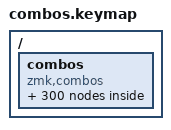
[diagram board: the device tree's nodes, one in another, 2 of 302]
/ {
    combos {
        compatible = "zmk,combos";
        #binding-cells = <2>;

        combo_the {
            key-positions = <12 11 17>;
            bindings      = < &kp T &kp H &kp E >;
        };

        combo_be {
            key-positions = <0 17>;
            bindings      = < &kp B &kp E >;
        };

        combo_and {
            key-positions = <16 9 22>;
            bindings      = < &kp A &kp N &kp D >;
        };

        combo_in {
            key-positions = <18 9>;
            bindings      = < &kp I &kp N >;
        };

        combo_have {
            key-positions = <11 16 20 17>;
            bindings      = < &kp H &kp A &kp V &kp E >;
        };

        combo_it {
            key-positions = <18 12>;
            bindings      = < &kp I &kp T >;
        };

        combo_that {
            key-positions = <12 11 16>;
            bindings      = < &kp T &kp H &kp A >;
        };

        combo_for {
            key-positions = <1 7 25>;
            bindings      = < &kp F &kp O &kp R >;
        };

        combo_you {
            key-positions = <14 7 8>;
            bindings      = < &kp Y &kp O &kp U >;
        };

        combo_he {
            key-positions = <11 17>;
            bindings      = < &kp H &kp E >;
        };

        combo_with {
            key-positions = <24 18 12 11>;
            bindings      = < &kp W &kp I &kp T &kp H >;
        };

        combo_do {
            key-positions = <22 7>;
            bindings      = < &kp D &kp O >;
        };

        combo_say {
            key-positions = <10 16 14>;
            bindings      = < &kp S &kp A &kp Y >;
        };

        combo_this {
            key-positions = <12 11 18 10>;
            bindings      = < &kp T &kp H &kp I &kp S >;
        };

        combo_they {
            key-positions = <12 11 17 14>;
            bindings      = < &kp T &kp H &kp E &kp Y >;
        };

        combo_at {
            key-positions = <16 12>;
            bindings      = < &kp A &kp T >;
        };

        combo_but {
            key-positions = <0 8 12>;
            bindings      = < &kp B &kp U &kp T >;
        };

        combo_we {
            key-positions = <24 17>;
            bindings      = < &kp W &kp E >;
        };

        combo_his {
            key-positions = <11 18 10>;
            bindings      = < &kp H &kp I &kp S >;
        };

        combo_from {
            key-positions = <1 25 7 13>;
            bindings      = < &kp F &kp R &kp O &kp M >;
        };

        combo_not {
            key-positions = <9 7 12>;
            bindings      = < &kp N &kp O &kp T >;
        };

        combo_by {
            key-positions = <0 14>;
            bindings      = < &kp B &kp Y >;
        };

        combo_she {
            key-positions = <10 11 17>;
            bindings      = < &kp S &kp H &kp E >;
        };

        combo_or {
            key-positions = <7 25>;
            bindings      = < &kp O &kp R >;
        };

        combo_as {
            key-positions = <16 10>;
            bindings      = < &kp A &kp S >;
        };

        combo_what {
            key-positions = <24 11 16 12>;
            bindings      = < &kp W &kp H &kp A &kp T >;
        };

        combo_go {
            key-positions = <6 7>;
            bindings      = < &kp G &kp O >;
        };

        combo_their {
            key-positions = <12 11 18>;
            bindings      = < &kp T &kp H &kp I >;
        };

        combo_can {
            key-positions = <15 16 9>;
            bindings      = < &kp C &kp A &kp N >;
        };

        combo_get {
            key-positions = <6 17 12>;
            bindings      = < &kp G &kp E &kp T >;
        };

        combo_if {
            key-positions = <18 1>;
            bindings      = < &kp I &kp F >;
        };

        combo_would {
            key-positions = <24 7 8>;
            bindings      = < &kp W &kp O &kp U >;
        };

        combo_her {
            key-positions = <11 17 25>;
            bindings      = < &kp H &kp E &kp R >;
        };

        combo_all {
            key-positions = <16 2>;
            bindings      = < &kp A &kp L >;
        };

        combo_my {
            key-positions = <13 14>;
            bindings      = < &kp M &kp Y >;
        };

        combo_make {
            key-positions = <13 16 3 17>;
            bindings      = < &kp M &kp A &kp K &kp E >;
        };

        combo_about {
            key-positions = <16 0 7>;
            bindings      = < &kp A &kp B &kp O >;
        };

        combo_know {
            key-positions = <3 9 7 24>;
            bindings      = < &kp K &kp N &kp O &kp W >;
        };

        combo_will {
            key-positions = <24 18 2>;
            bindings      = < &kp W &kp I &kp L >;
        };

        combo_up {
            key-positions = <8 5>;
            bindings      = < &kp U &kp P >;
        };

        combo_one {
            key-positions = <7 9 17>;
            bindings      = < &kp O &kp N &kp E >;
        };

        combo_time {
            key-positions = <12 18 13 17>;
            bindings      = < &kp T &kp I &kp M &kp E >;
        };

        combo_there {
            key-positions = <12 11 17 25>;
            bindings      = < &kp T &kp H &kp E &kp R >;
        };

        combo_year {
            key-positions = <14 17 16 25>;
            bindings      = < &kp Y &kp E &kp A &kp R >;
        };

        combo_so {
            key-positions = <10 7>;
            bindings      = < &kp S &kp O >;
        };

        combo_think {
            key-positions = <12 11 3>;
            bindings      = < &kp T &kp H &kp K >;
        };

        combo_when {
            key-positions = <24 11 17 9>;
            bindings      = < &kp W &kp H &kp E &kp N >;
        };

        combo_which {
            key-positions = <24 11 18 15>;
            bindings      = < &kp W &kp H &kp I &kp C >;
        };

        combo_them {
            key-positions = <12 11 17 13>;
            bindings      = < &kp T &kp H &kp E &kp M >;
        };

        combo_some {
            key-positions = <10 7 13 17>;
            bindings      = < &kp S &kp O &kp M &kp E >;
        };

        combo_me {
            key-positions = <13 17>;
            bindings      = < &kp M &kp E >;
        };

        combo_people {
            key-positions = <5 17 7 2>;
            bindings      = < &kp P &kp E &kp O &kp L >;
        };

        combo_take {
            key-positions = <12 16 3 17>;
            bindings      = < &kp T &kp A &kp K &kp E >;
        };

        combo_out {
            key-positions = <7 8 12>;
            bindings      = < &kp O &kp U &kp T >;
        };

        combo_just {
            key-positions = <21 8 10 12>;
            bindings      = < &kp J &kp U &kp S &kp T >;
        };

        combo_see {
            key-positions = <10 17>;
            bindings      = < &kp S &kp E >;
        };

        combo_him {
            key-positions = <11 18 13>;
            bindings      = < &kp H &kp I &kp M >;
        };

        combo_your {
            key-positions = <14 7 8 25>;
            bindings      = < &kp Y &kp O &kp U &kp R >;
        };

        combo_come {
            key-positions = <15 7 13 17>;
            bindings      = < &kp C &kp O &kp M &kp E >;
        };

        combo_could {
            key-positions = <15 7 8>;
            bindings      = < &kp C &kp O &kp U >;
        };

        combo_now {
            key-positions = <9 7 24>;
            bindings      = < &kp N &kp O &kp W >;
        };

        combo_than {
            key-positions = <12 11 16 9>;
            bindings      = < &kp T &kp H &kp A &kp N >;
        };

        combo_like {
            key-positions = <2 18 3 17>;
            bindings      = < &kp L &kp I &kp K &kp E >;
        };

        combo_how {
            key-positions = <11 7 24>;
            bindings      = < &kp H &kp O &kp W >;
        };

        combo_then {
            key-positions = <12 11 17 9>;
            bindings      = < &kp T &kp H &kp E &kp N >;
        };

        combo_two {
            key-positions = <12 24 7>;
            bindings      = < &kp T &kp W &kp O >;
        };

        combo_more {
            key-positions = <13 7 25 17>;
            bindings      = < &kp M &kp O &kp R &kp E >;
        };

        combo_these {
            key-positions = <12 11 17 10>;
            bindings      = < &kp T &kp H &kp E &kp S >;
        };

        combo_want {
            key-positions = <24 16 9 12>;
            bindings      = < &kp W &kp A &kp N &kp T >;
        };

        combo_way {
            key-positions = <24 16 14>;
            bindings      = < &kp W &kp A &kp Y >;
        };

        combo_look {
            key-positions = <2 7 3>;
            bindings      = < &kp L &kp O &kp K >;
        };

        combo_first {
            key-positions = <1 18 25>;
            bindings      = < &kp F &kp I &kp R >;
        };

        combo_also {
            key-positions = <16 2 10 7>;
            bindings      = < &kp A &kp L &kp S &kp O >;
        };

        combo_new {
            key-positions = <9 17 24>;
            bindings      = < &kp N &kp E &kp W >;
        };

        combo_day {
            key-positions = <22 16 14>;
            bindings      = < &kp D &kp A &kp Y >;
        };

        combo_use {
            key-positions = <8 10 17>;
            bindings      = < &kp U &kp S &kp E >;
        };

        combo_man {
            key-positions = <13 16 9>;
            bindings      = < &kp M &kp A &kp N >;
        };

        combo_find {
            key-positions = <1 18 9 22>;
            bindings      = < &kp F &kp I &kp N &kp D >;
        };

        combo_thing {
            key-positions = <12 11 9>;
            bindings      = < &kp T &kp H &kp N >;
        };

        combo_give {
            key-positions = <6 18 20 17>;
            bindings      = < &kp G &kp I &kp V &kp E >;
        };

        combo_many {
            key-positions = <13 16 9 14>;
            bindings      = < &kp M &kp A &kp N &kp Y >;
        };

        combo_well {
            key-positions = <24 17 2>;
            bindings      = < &kp W &kp E &kp L >;
        };

        combo_only {
            key-positions = <7 9 2 14>;
            bindings      = < &kp O &kp N &kp L &kp Y >;
        };

        combo_those {
            key-positions = <12 11 10>;
            bindings      = < &kp T &kp H &kp S >;
        };

        combo_tell {
            key-positions = <12 17 2>;
            bindings      = < &kp T &kp E &kp L >;
        };

        combo_even {
            key-positions = <17 20 9>;
            bindings      = < &kp E &kp V &kp N >;
        };

        combo_back {
            key-positions = <0 16 15 3>;
            bindings      = < &kp B &kp A &kp C &kp K >;
        };

        combo_any {
            key-positions = <16 9 14>;
            bindings      = < &kp A &kp N &kp Y >;
        };

        combo_good {
            key-positions = <6 7 22>;
            bindings      = < &kp G &kp O &kp D >;
        };

        combo_woman {
            key-positions = <24 7 13>;
            bindings      = < &kp W &kp O &kp M >;
        };

        combo_through {
            key-positions = <12 11 25>;
            bindings      = < &kp T &kp H &kp R >;
        };

        combo_us {
            key-positions = <8 10>;
            bindings      = < &kp U &kp S >;
        };

        combo_life {
            key-positions = <2 18 1 17>;
            bindings      = < &kp L &kp I &kp F &kp E >;
        };

        combo_child {
            key-positions = <15 11 2>;
            bindings      = < &kp C &kp H &kp L >;
        };

        combo_work {
            key-positions = <24 7 25 3>;
            bindings      = < &kp W &kp O &kp R &kp K >;
        };

        combo_down {
            key-positions = <22 7 24 9>;
            bindings      = < &kp D &kp O &kp W &kp N >;
        };

        combo_may {
            key-positions = <13 16 14>;
            bindings      = < &kp M &kp A &kp Y >;
        };

        combo_after {
            key-positions = <16 1 17>;
            bindings      = < &kp A &kp F &kp E >;
        };

        combo_should {
            key-positions = <10 11 7>;
            bindings      = < &kp S &kp H &kp O >;
        };

        combo_call {
            key-positions = <15 16 2>;
            bindings      = < &kp C &kp A &kp L >;
        };

        combo_world {
            key-positions = <24 7 25>;
            bindings      = < &kp W &kp O &kp R >;
        };

        combo_over {
            key-positions = <7 20 17 25>;
            bindings      = < &kp O &kp V &kp E &kp R >;
        };

        combo_school {
            key-positions = <10 15 11>;
            bindings      = < &kp S &kp C &kp H >;
        };

        combo_still {
            key-positions = <10 12 18 2>;
            bindings      = < &kp S &kp T &kp I &kp L >;
        };

        combo_try {
            key-positions = <12 25 14>;
            bindings      = < &kp T &kp R &kp Y >;
        };

        combo_last {
            key-positions = <2 16 10 12>;
            bindings      = < &kp L &kp A &kp S &kp T >;
        };

        combo_ask {
            key-positions = <16 10 3>;
            bindings      = < &kp A &kp S &kp K >;
        };

        combo_too {
            key-positions = <12 7>;
            bindings      = < &kp T &kp O >;
        };

        combo_feel {
            key-positions = <1 17 2>;
            bindings      = < &kp F &kp E &kp L >;
        };

        combo_state {
            key-positions = <10 12 16 17>;
            bindings      = < &kp S &kp T &kp A &kp E >;
        };

        combo_never {
            key-positions = <9 17 20 25>;
            bindings      = < &kp N &kp E &kp V &kp R >;
        };

        combo_between {
            key-positions = <0 17 12>;
            bindings      = < &kp B &kp E &kp T >;
        };

        combo_high {
            key-positions = <11 18 6>;
            bindings      = < &kp H &kp I &kp G >;
        };

        combo_most {
            key-positions = <13 7 10 12>;
            bindings      = < &kp M &kp O &kp S &kp T >;
        };

        combo_much {
            key-positions = <13 8 15 11>;
            bindings      = < &kp M &kp U &kp C &kp H >;
        };

        combo_family {
            key-positions = <1 16 13>;
            bindings      = < &kp F &kp A &kp M >;
        };

        combo_leave {
            key-positions = <2 17 16 20>;
            bindings      = < &kp L &kp E &kp A &kp V >;
        };

        combo_put {
            key-positions = <5 8 12>;
            bindings      = < &kp P &kp U &kp T >;
        };

        combo_old {
            key-positions = <7 2 22>;
            bindings      = < &kp O &kp L &kp D >;
        };

        combo_while {
            key-positions = <24 11 18>;
            bindings      = < &kp W &kp H &kp I >;
        };

        combo_keep {
            key-positions = <3 17 5>;
            bindings      = < &kp K &kp E &kp P >;
        };

        combo_student {
            key-positions = <10 22 9>;
            bindings      = < &kp S &kp D &kp N >;
        };

        combo_why {
            key-positions = <24 11 14>;
            bindings      = < &kp W &kp H &kp Y >;
        };

        combo_great {
            key-positions = <6 25 17>;
            bindings      = < &kp G &kp R &kp E >;
        };

        combo_same {
            key-positions = <10 16 13 17>;
            bindings      = < &kp S &kp A &kp M &kp E >;
        };

        combo_big {
            key-positions = <0 18 6>;
            bindings      = < &kp B &kp I &kp G >;
        };

        combo_group {
            key-positions = <6 25 7>;
            bindings      = < &kp G &kp R &kp O >;
        };

        combo_begin {
            key-positions = <0 17 6>;
            bindings      = < &kp B &kp E &kp G >;
        };

        combo_seem {
            key-positions = <10 17 13>;
            bindings      = < &kp S &kp E &kp M >;
        };

        combo_country {
            key-positions = <15 7 9>;
            bindings      = < &kp C &kp O &kp N >;
        };

        combo_help {
            key-positions = <11 17 2 5>;
            bindings      = < &kp H &kp E &kp L &kp P >;
        };

        combo_talk {
            key-positions = <12 16 2 3>;
            bindings      = < &kp T &kp A &kp L &kp K >;
        };

        combo_where {
            key-positions = <24 11 17 25>;
            bindings      = < &kp W &kp H &kp E &kp R >;
        };

        combo_turn {
            key-positions = <12 8 25 9>;
            bindings      = < &kp T &kp U &kp R &kp N >;
        };

        combo_problem {
            key-positions = <5 25 0>;
            bindings      = < &kp P &kp R &kp B >;
        };

        combo_every {
            key-positions = <17 20 25 14>;
            bindings      = < &kp E &kp V &kp R &kp Y >;
        };

        combo_start {
            key-positions = <10 12 16 25>;
            bindings      = < &kp S &kp T &kp A &kp R >;
        };

        combo_hand {
            key-positions = <11 16 9 22>;
            bindings      = < &kp H &kp A &kp N &kp D >;
        };

        combo_might {
            key-positions = <13 18 6>;
            bindings      = < &kp M &kp I &kp G >;
        };

        combo_show {
            key-positions = <10 11 7 24>;
            bindings      = < &kp S &kp H &kp O &kp W >;
        };

        combo_part {
            key-positions = <5 16 25 12>;
            bindings      = < &kp P &kp A &kp R &kp T >;
        };

        combo_against {
            key-positions = <16 6 18>;
            bindings      = < &kp A &kp G &kp I >;
        };

        combo_place {
            key-positions = <5 2 16>;
            bindings      = < &kp P &kp L &kp A >;
        };

        combo_such {
            key-positions = <10 8 15 11>;
            bindings      = < &kp S &kp U &kp C &kp H >;
        };

        combo_again {
            key-positions = <16 6 18 9>;
            bindings      = < &kp A &kp G &kp I &kp N >;
        };

        combo_few {
            key-positions = <1 17 24>;
            bindings      = < &kp F &kp E &kp W >;
        };

        combo_case {
            key-positions = <15 16 10 17>;
            bindings      = < &kp C &kp A &kp S &kp E >;
        };

        combo_week {
            key-positions = <24 17 3>;
            bindings      = < &kp W &kp E &kp K >;
        };

        combo_company {
            key-positions = <15 13 9>;
            bindings      = < &kp C &kp M &kp N >;
        };

        combo_system {
            key-positions = <10 14 12>;
            bindings      = < &kp S &kp Y &kp T >;
        };

        combo_each {
            key-positions = <17 16 15 11>;
            bindings      = < &kp E &kp A &kp C &kp H >;
        };

        combo_right {
            key-positions = <25 18 6>;
            bindings      = < &kp R &kp I &kp G >;
        };

        combo_hear {
            key-positions = <11 17 16 25>;
            bindings      = < &kp H &kp E &kp A &kp R >;
        };

        combo_question {
            key-positions = <4 8 9>;
            bindings      = < &kp Q &kp U &kp N >;
        };

        combo_during {
            key-positions = <22 8 25>;
            bindings      = < &kp D &kp U &kp R >;
        };

        combo_play {
            key-positions = <5 2 16 14>;
            bindings      = < &kp P &kp L &kp A &kp Y >;
        };

        combo_run {
            key-positions = <25 8 9>;
            bindings      = < &kp R &kp U &kp N >;
        };

        combo_small {
            key-positions = <10 13 16 2>;
            bindings      = < &kp S &kp M &kp A &kp L >;
        };

        combo_number {
            key-positions = <9 8 0>;
            bindings      = < &kp N &kp U &kp B >;
        };

        combo_off {
            key-positions = <7 1>;
            bindings      = < &kp O &kp F >;
        };

        combo_always {
            key-positions = <16 2 24>;
            bindings      = < &kp A &kp L &kp W >;
        };

        combo_move {
            key-positions = <13 7 20 17>;
            bindings      = < &kp M &kp O &kp V &kp E >;
        };

        combo_night {
            key-positions = <9 18 11>;
            bindings      = < &kp N &kp I &kp H >;
        };

        combo_live {
            key-positions = <2 18 20 17>;
            bindings      = < &kp L &kp I &kp V &kp E >;
        };

        combo_point {
            key-positions = <5 7 18>;
            bindings      = < &kp P &kp O &kp I >;
        };

        combo_believe {
            key-positions = <0 17 2>;
            bindings      = < &kp B &kp E &kp L >;
        };

        combo_hold {
            key-positions = <11 7 2 22>;
            bindings      = < &kp H &kp O &kp L &kp D >;
        };

        combo_bring {
            key-positions = <0 25 18>;
            bindings      = < &kp B &kp R &kp I >;
        };

        combo_happen {
            key-positions = <11 16 5>;
            bindings      = < &kp H &kp A &kp P >;
        };

        combo_next {
            key-positions = <9 17 19 12>;
            bindings      = < &kp N &kp E &kp X &kp T >;
        };

        combo_before {
            key-positions = <0 17 1>;
            bindings      = < &kp B &kp E &kp F >;
        };

        combo_large {
            key-positions = <2 16 25>;
            bindings      = < &kp L &kp A &kp R >;
        };

        combo_million {
            key-positions = <13 18 2>;
            bindings      = < &kp M &kp I &kp L >;
        };

        combo_must {
            key-positions = <13 8 10 12>;
            bindings      = < &kp M &kp U &kp S &kp T >;
        };

        combo_home {
            key-positions = <11 7 13 17>;
            bindings      = < &kp H &kp O &kp M &kp E >;
        };

        combo_under {
            key-positions = <8 9 22>;
            bindings      = < &kp U &kp N &kp D >;
        };

        combo_water {
            key-positions = <24 16 17>;
            bindings      = < &kp W &kp A &kp E >;
        };

        combo_room {
            key-positions = <25 7 13>;
            bindings      = < &kp R &kp O &kp M >;
        };

        combo_write {
            key-positions = <24 25 18>;
            bindings      = < &kp W &kp R &kp I >;
        };

        combo_mother {
            key-positions = <13 12 11>;
            bindings      = < &kp M &kp T &kp H >;
        };

        combo_money {
            key-positions = <13 7 9>;
            bindings      = < &kp M &kp O &kp N >;
        };

        combo_story {
            key-positions = <10 12 7>;
            bindings      = < &kp S &kp T &kp O >;
        };

        combo_young {
            key-positions = <14 7 9>;
            bindings      = < &kp Y &kp O &kp N >;
        };

        combo_fact {
            key-positions = <1 16 15 12>;
            bindings      = < &kp F &kp A &kp C &kp T >;
        };

        combo_month {
            key-positions = <13 7 11>;
            bindings      = < &kp M &kp O &kp H >;
        };

        combo_lot {
            key-positions = <2 7 12>;
            bindings      = < &kp L &kp O &kp T >;
        };

        combo_study {
            key-positions = <10 12 8>;
            bindings      = < &kp S &kp T &kp U >;
        };

        combo_book {
            key-positions = <0 7 3>;
            bindings      = < &kp B &kp O &kp K >;
        };

        combo_eye {
            key-positions = <17 14>;
            bindings      = < &kp E &kp Y >;
        };

        combo_word {
            key-positions = <24 7 25 22>;
            bindings      = < &kp W &kp O &kp R &kp D >;
        };

        combo_though {
            key-positions = <12 11 8>;
            bindings      = < &kp T &kp H &kp U >;
        };

        combo_side {
            key-positions = <10 18 22 17>;
            bindings      = < &kp S &kp I &kp D &kp E >;
        };

        combo_four {
            key-positions = <1 7 8 25>;
            bindings      = < &kp F &kp O &kp U &kp R >;
        };

        combo_head {
            key-positions = <11 17 16 22>;
            bindings      = < &kp H &kp E &kp A &kp D >;
        };

        combo_far {
            key-positions = <1 16 25>;
            bindings      = < &kp F &kp A &kp R >;
        };

        combo_black {
            key-positions = <0 2 16>;
            bindings      = < &kp B &kp L &kp A >;
        };

        combo_long {
            key-positions = <2 7 9 6>;
            bindings      = < &kp L &kp O &kp N &kp G >;
        };

        combo_both {
            key-positions = <0 7 12 11>;
            bindings      = < &kp B &kp O &kp T &kp H >;
        };

        combo_little {
            key-positions = <2 18 12 17>;
            bindings      = < &kp L &kp I &kp T &kp E >;
        };

        combo_house {
            key-positions = <11 7 8>;
            bindings      = < &kp H &kp O &kp U >;
        };

        combo_yes {
            key-positions = <14 17 10>;
            bindings      = < &kp Y &kp E &kp S >;
        };

        combo_since {
            key-positions = <10 18 9>;
            bindings      = < &kp S &kp I &kp N >;
        };

        combo_provide {
            key-positions = <5 25 18>;
            bindings      = < &kp P &kp R &kp I >;
        };

        combo_friend {
            key-positions = <1 25 17>;
            bindings      = < &kp F &kp R &kp E >;
        };

        combo_sit {
            key-positions = <10 18 12>;
            bindings      = < &kp S &kp I &kp T >;
        };

        combo_until {
            key-positions = <8 9 12>;
            bindings      = < &kp U &kp N &kp T >;
        };

        combo_power {
            key-positions = <5 7 24>;
            bindings      = < &kp P &kp O &kp W >;
        };

        combo_hour {
            key-positions = <11 7 8 25>;
            bindings      = < &kp H &kp O &kp U &kp R >;
        };

        combo_game {
            key-positions = <6 16 13 17>;
            bindings      = < &kp G &kp A &kp M &kp E >;
        };

        combo_often {
            key-positions = <7 1 12>;
            bindings      = < &kp O &kp F &kp T >;
        };

        combo_yet {
            key-positions = <14 17 12>;
            bindings      = < &kp Y &kp E &kp T >;
        };

        combo_line {
            key-positions = <2 18 9 17>;
            bindings      = < &kp L &kp I &kp N &kp E >;
        };

        combo_end {
            key-positions = <17 9 22>;
            bindings      = < &kp E &kp N &kp D >;
        };

        combo_among {
            key-positions = <16 13 7>;
            bindings      = < &kp A &kp M &kp O >;
        };

        combo_ever {
            key-positions = <17 20 25>;
            bindings      = < &kp E &kp V &kp R >;
        };

        combo_stand {
            key-positions = <10 12 16>;
            bindings      = < &kp S &kp T &kp A >;
        };

        combo_bad {
            key-positions = <0 16 22>;
            bindings      = < &kp B &kp A &kp D >;
        };

        combo_pay {
            key-positions = <5 16 14>;
            bindings      = < &kp P &kp A &kp Y >;
        };

        combo_meet {
            key-positions = <13 17 12>;
            bindings      = < &kp M &kp E &kp T >;
        };

        combo_car {
            key-positions = <15 16 25>;
            bindings      = < &kp C &kp A &kp R >;
        };

        combo_city {
            key-positions = <15 18 12 14>;
            bindings      = < &kp C &kp I &kp T &kp Y >;
        };

        combo_include {
            key-positions = <18 9 15>;
            bindings      = < &kp I &kp N &kp C >;
        };

        combo_continue {
            key-positions = <15 7 18>;
            bindings      = < &kp C &kp O &kp I >;
        };

        combo_name {
            key-positions = <9 16 13 17>;
            bindings      = < &kp N &kp A &kp M &kp E >;
        };

        combo_once {
            key-positions = <7 9 15 17>;
            bindings      = < &kp O &kp N &kp C &kp E >;
        };

        combo_white {
            key-positions = <24 11 12>;
            bindings      = < &kp W &kp H &kp T >;
        };

        combo_least {
            key-positions = <2 16 10>;
            bindings      = < &kp L &kp A &kp S >;
        };

        combo_learn {
            key-positions = <2 17 16>;
            bindings      = < &kp L &kp E &kp A >;
        };

        combo_real {
            key-positions = <25 17 16 2>;
            bindings      = < &kp R &kp E &kp A &kp L >;
        };

        combo_change {
            key-positions = <15 11 16>;
            bindings      = < &kp C &kp H &kp A >;
        };

        combo_team {
            key-positions = <12 17 16 13>;
            bindings      = < &kp T &kp E &kp A &kp M >;
        };

        combo_minute {
            key-positions = <13 18 9>;
            bindings      = < &kp M &kp I &kp N >;
        };

        combo_best {
            key-positions = <0 17 10 12>;
            bindings      = < &kp B &kp E &kp S &kp T >;
        };

        combo_several {
            key-positions = <10 17 20>;
            bindings      = < &kp S &kp E &kp V >;
        };

        combo_idea {
            key-positions = <18 22 17 16>;
            bindings      = < &kp I &kp D &kp E &kp A >;
        };

        combo_body {
            key-positions = <0 7 22 14>;
            bindings      = < &kp B &kp O &kp D &kp Y >;
        };

        combo_nothing {
            key-positions = <9 7 11>;
            bindings      = < &kp N &kp O &kp H >;
        };

        combo_ago {
            key-positions = <16 6 7>;
            bindings      = < &kp A &kp G &kp O >;
        };

        combo_lead {
            key-positions = <2 17 16 22>;
            bindings      = < &kp L &kp E &kp A &kp D >;
        };

        combo_watch {
            key-positions = <24 16 12>;
            bindings      = < &kp W &kp A &kp T >;
        };

        combo_together {
            key-positions = <12 6 11>;
            bindings      = < &kp T &kp G &kp H >;
        };

        combo_follow {
            key-positions = <1 7 2 24>;
            bindings      = < &kp F &kp O &kp L &kp W >;
        };

        combo_parent {
            key-positions = <5 16 17>;
            bindings      = < &kp P &kp A &kp E >;
        };

        combo_stop {
            key-positions = <10 12 7 5>;
            bindings      = < &kp S &kp T &kp O &kp P >;
        };

        combo_face {
            key-positions = <1 16 15 17>;
            bindings      = < &kp F &kp A &kp C &kp E >;
        };

        combo_create {
            key-positions = <15 25 12>;
            bindings      = < &kp C &kp R &kp T >;
        };

        combo_speak {
            key-positions = <10 5 3>;
            bindings      = < &kp S &kp P &kp K >;
        };

        combo_read {
            key-positions = <25 17 16 22>;
            bindings      = < &kp R &kp E &kp A &kp D >;
        };

        combo_level {
            key-positions = <2 17 20>;
            bindings      = < &kp L &kp E &kp V >;
        };

        combo_allow {
            key-positions = <16 2 7 24>;
            bindings      = < &kp A &kp L &kp O &kp W >;
        };

        combo_add {
            key-positions = <16 22>;
            bindings      = < &kp A &kp D >;
        };

        combo_office {
            key-positions = <7 1 18>;
            bindings      = < &kp O &kp F &kp I >;
        };

        combo_spend {
            key-positions = <10 5 9>;
            bindings      = < &kp S &kp P &kp N >;
        };

        combo_door {
            key-positions = <22 7 25>;
            bindings      = < &kp D &kp O &kp R >;
        };

        combo_person {
            key-positions = <5 17 10>;
            bindings      = < &kp P &kp E &kp S >;
        };

        combo_sure {
            key-positions = <10 8 25 17>;
            bindings      = < &kp S &kp U &kp R &kp E >;
        };

        combo_war {
            key-positions = <24 16 25>;
            bindings      = < &kp W &kp A &kp R >;
        };

        combo_history {
            key-positions = <11 18 7>;
            bindings      = < &kp H &kp I &kp O >;
        };

        combo_party {
            key-positions = <5 25 14>;
            bindings      = < &kp P &kp R &kp Y >;
        };

        combo_result {
            key-positions = <25 17 8>;
            bindings      = < &kp R &kp E &kp U >;
        };

        combo_open {
            key-positions = <7 5 17 9>;
            bindings      = < &kp O &kp P &kp E &kp N >;
        };

        combo_morning {
            key-positions = <13 7 18>;
            bindings      = < &kp M &kp O &kp I >;
        };

        combo_walk {
            key-positions = <24 16 2 3>;
            bindings      = < &kp W &kp A &kp L &kp K >;
        };

        combo_reason {
            key-positions = <25 10 9>;
            bindings      = < &kp R &kp S &kp N >;
        };

        combo_low {
            key-positions = <2 7 24>;
            bindings      = < &kp L &kp O &kp W >;
        };

        combo_girl {
            key-positions = <6 18 25 2>;
            bindings      = < &kp G &kp I &kp R &kp L >;
        };

        combo_early {
            key-positions = <17 16 14>;
            bindings      = < &kp E &kp A &kp Y >;
        };

        combo_food {
            key-positions = <1 7 22>;
            bindings      = < &kp F &kp O &kp D >;
        };

        combo_moment {
            key-positions = <13 7 17>;
            bindings      = < &kp M &kp O &kp E >;
        };

        combo_air {
            key-positions = <16 18 25>;
            bindings      = < &kp A &kp I &kp R >;
        };

        combo_force {
            key-positions = <1 7 15>;
            bindings      = < &kp F &kp O &kp C >;
        };

        combo_enough {
            key-positions = <17 9 8>;
            bindings      = < &kp E &kp N &kp U >;
        };

        combo_remember {
            key-positions = <25 17 13 0>;
            bindings      = < &kp R &kp E &kp M &kp B >;
        };

        combo_second {
            key-positions = <10 17 15>;
            bindings      = < &kp S &kp E &kp C >;
        };

        combo_boy {
            key-positions = <0 7 14>;
            bindings      = < &kp B &kp O &kp Y >;
        };

        combo_toward {
            key-positions = <12 7 16>;
            bindings      = < &kp T &kp O &kp A >;
        };

        combo_able {
            key-positions = <16 0 2 17>;
            bindings      = < &kp A &kp B &kp L &kp E >;
        };

        combo_age {
            key-positions = <16 6 17>;
            bindings      = < &kp A &kp G &kp E >;
        };

        combo_love {
            key-positions = <2 7 20 17>;
            bindings      = < &kp L &kp O &kp V &kp E >;
        };

        combo_process {
            key-positions = <5 7 15>;
            bindings      = < &kp P &kp O &kp C >;
        };

        combo_music {
            key-positions = <13 8 10>;
            bindings      = < &kp M &kp U &kp S >;
        };

        combo_consider {
            key-positions = <15 9 22>;
            bindings      = < &kp C &kp N &kp D >;
        };

        combo_appear {
            key-positions = <16 5 17 25>;
            bindings      = < &kp A &kp P &kp E &kp R >;
        };

        combo_buy {
            key-positions = <0 8 14>;
            bindings      = < &kp B &kp U &kp Y >;
        };

        combo_human {
            key-positions = <11 8 13>;
            bindings      = < &kp H &kp U &kp M >;
        };

        combo_wait {
            key-positions = <24 16 18 12>;
            bindings      = < &kp W &kp A &kp I &kp T >;
        };

        combo_serve {
            key-positions = <10 17 25 20>;
            bindings      = < &kp S &kp E &kp R &kp V >;
        };

        combo_market {
            key-positions = <13 16 3>;
            bindings      = < &kp M &kp A &kp K >;
        };

        combo_send {
            key-positions = <10 17 9 22>;
            bindings      = < &kp S &kp E &kp N &kp D >;
        };

        combo_expect {
            key-positions = <17 5 15>;
            bindings      = < &kp E &kp P &kp C >;
        };

        combo_build {
            key-positions = <0 8 18>;
            bindings      = < &kp B &kp U &kp I >;
        };

        combo_stay {
            key-positions = <10 12 16 14>;
            bindings      = < &kp S &kp T &kp A &kp Y >;
        };

        combo_fall {
            key-positions = <1 16 2>;
            bindings      = < &kp F &kp A &kp L >;
        };

        combo_oh {
            key-positions = <7 11>;
            bindings      = < &kp O &kp H >;
        };

        combo_nation {
            key-positions = <9 16 7>;
            bindings      = < &kp N &kp A &kp O >;
        };

        combo_plan {
            key-positions = <5 2 16 9>;
            bindings      = < &kp P &kp L &kp A &kp N >;
        };

        combo_cut {
            key-positions = <15 8 12>;
            bindings      = < &kp C &kp U &kp T >;
        };

        combo_interest {
            key-positions = <18 9 25>;
            bindings      = < &kp I &kp N &kp R >;
        };

        combo_death {
            key-positions = <22 17 11>;
            bindings      = < &kp D &kp E &kp H >;
        };

        combo_course {
            key-positions = <15 7 10>;
            bindings      = < &kp C &kp O &kp S >;
        };

    };
};
